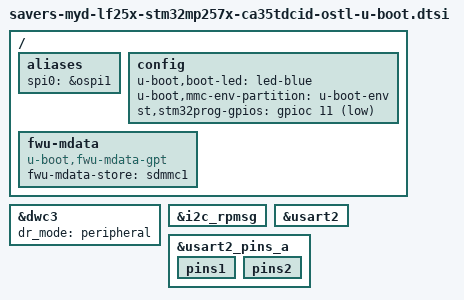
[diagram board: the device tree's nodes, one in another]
// SPDX-License-Identifier: GPL-2.0-or-later OR BSD-3-Clause
/*
 * Copyright (C) Savers 2024 - All Rights Reserved
 *
 * U-Boot overlay for the Savers MYD-LF25X, based on MYiR's vanilla
 * myb-stm32mp257x-1GB-u-boot.dtsi (targets nodes provided by myb-base).
 */

#include "stm32mp25-u-boot.dtsi"

/ {
	aliases {
		spi0 = &ospi1;
	};

	config {
		u-boot,boot-led = "led-blue";
		u-boot,mmc-env-partition = "u-boot-env";
		st,stm32prog-gpios = <&gpioc 11 (GPIO_ACTIVE_LOW | GPIO_PULL_UP)>;
	};

	fwu-mdata {
		compatible = "u-boot,fwu-mdata-gpt";
		fwu-mdata-store = <&sdmmc1>;
	};
};

&dwc3 {
	dr_mode = "peripheral";
	/delete-node/ port;
};

&i2c_rpmsg {
	/delete-node/ typec@35;
};

&usart2 {
	bootph-all;
};

&usart2_pins_a {
	bootph-all;
	pins1 {
		bootph-all;
	};
	pins2 {
		bootph-all;
	};
};
